VERSION ""

NS_ :

BS_:

BU_: EON XXX INTERCEPTOR ANY ACTUATOR SAFETY

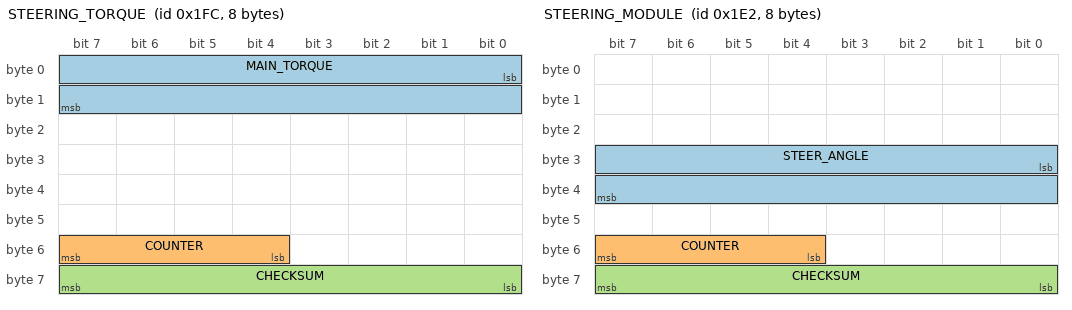
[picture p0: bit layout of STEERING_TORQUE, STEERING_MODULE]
BO_ 508 STEERING_TORQUE: 8 XXX
 SG_ MAIN_TORQUE : 0|16@1- (0.1,0) [0|65535] "" XXX
 SG_ COUNTER : 55|4@0+ (1,0) [0|15] "" XXX
 SG_ CHECKSUM : 56|8@1+ (1,0) [0|255] "" XXX

BO_ 482 STEERING_MODULE: 8 XXX
 SG_ STEER_ANGLE : 24|16@1- (0.1,0) [0|255] "" XXX
 SG_ COUNTER : 55|4@0+ (1,0) [0|15] "" XXX
 SG_ CHECKSUM : 56|8@1+ (1,0) [0|255] "" XXX

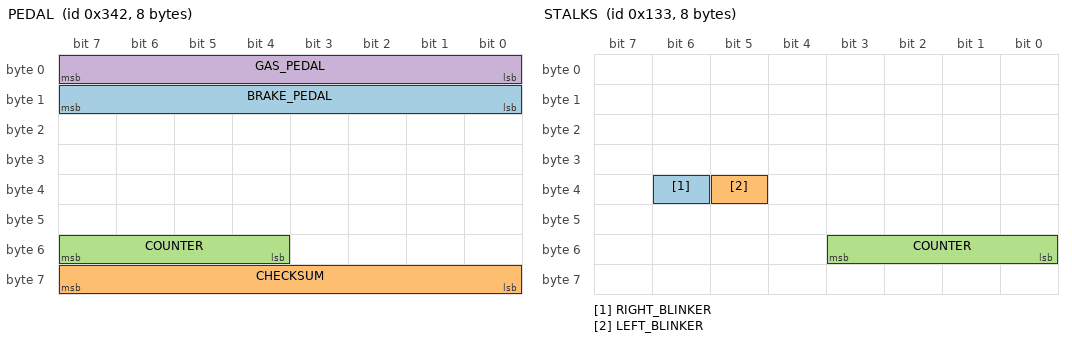
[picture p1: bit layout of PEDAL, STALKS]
BO_ 834 PEDAL: 8 XXX
 SG_ BRAKE_PEDAL : 8|8@1+ (0.01,0) [0|255] "" XXX
 SG_ CHECKSUM : 56|8@1+ (1,0) [0|255] "" XXX
 SG_ COUNTER : 55|4@0+ (1,0) [0|15] "" XXX
 SG_ GAS_PEDAL : 0|8@1+ (0.01,0) [0|255] "" XXX

BO_ 660 SEATBELT: 8 XXX
 SG_ SEATBELT_DRIVER : 17|1@0+ (1,0) [0|1] "" XXX

BO_ 307 STALKS: 8 XXX
 SG_ RIGHT_BLINKER : 38|1@0+ (1,0) [0|1] "" XXX
 SG_ LEFT_BLINKER : 37|1@0+ (1,0) [0|1] "" XXX
 SG_ COUNTER : 48|4@1+ (1,0) [0|15] "" XXX

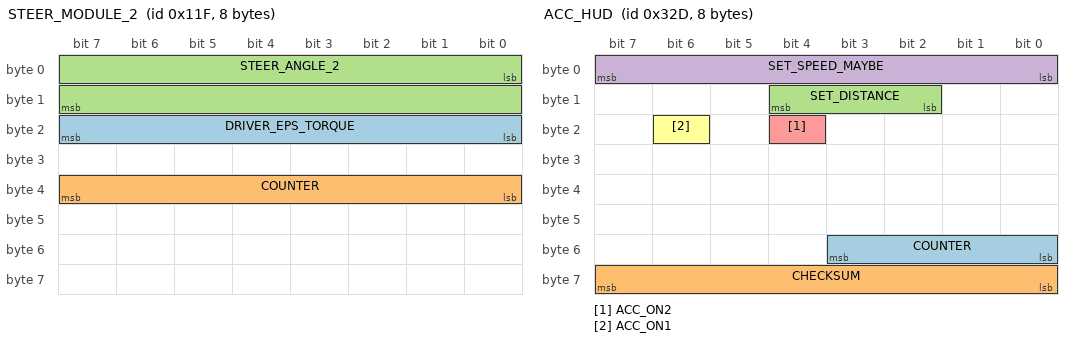
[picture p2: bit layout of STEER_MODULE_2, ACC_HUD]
BO_ 287 STEER_MODULE_2: 8 XXX
 SG_ DRIVER_EPS_TORQUE : 16|8@1+ (1,0) [0|255] "" XXX
 SG_ COUNTER : 39|8@0+ (1,0) [0|255] "" XXX
 SG_ STEER_ANGLE_2 : 0|16@1- (0.1,0) [0|65535] "" XXX

BO_ 944 PCM_BUTTONS: 8 XXX

BO_ 544 PEDAL_PRESSED: 8 XXX
 SG_ PEDAL_PRESSED_ACTIVE_LOW : 12|1@0+ (1,0) [0|1] "" XXX

BO_ 578 DRIVE_STATE: 8 XXX
 SG_ BRAKE_PRESSED : 37|1@0+ (1,0) [0|1] "" XXX
 SG_ GEAR : 40|3@1+ (1,0) [0|7] "" XXX

BO_ 813 ACC_HUD: 8 XXX
 SG_ COUNTER : 48|4@1+ (1,0) [0|15] "" XXX
 SG_ CHECKSUM : 56|8@1+ (1,0) [0|255] "" XXX
 SG_ SET_DISTANCE : 12|3@0+ (1,0) [0|7] "" XXX
 SG_ SET_SPEED_MAYBE : 0|8@1+ (1,0) [0|255] "" XXX
 SG_ ACC_ON2 : 20|1@0+ (1,0) [0|1] "" XXX
 SG_ ACC_ON1 : 22|1@0+ (1,0) [0|1] "" XXX

BO_ 790 LKAS_HUD: 8 XXX
 SG_ LKAS_ON : 36|1@0+ (1,0) [0|1] "" XXX

BO_ 814 ACC_RELATED: 8 XXX

BO_ 1048 BSM: 8 XXX
 SG_ LEFT_APPROACH : 23|1@0+ (1,0) [0|1] "" XXX
 SG_ BSM_RELATED : 24|1@0+ (1,0) [0|1] "" XXX

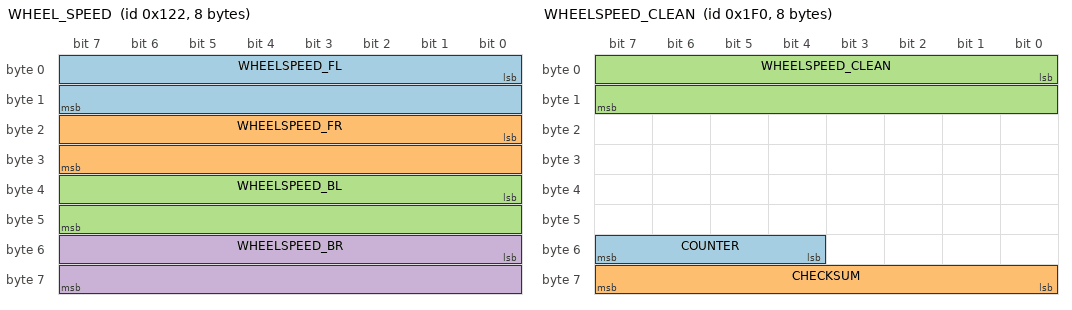
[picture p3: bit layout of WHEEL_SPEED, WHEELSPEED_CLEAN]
BO_ 290 WHEEL_SPEED: 8 XXX
 SG_ WHEELSPEED_FL : 0|16@1- (0.1,0) [0|65535] "" XXX
 SG_ WHEELSPEED_FR : 16|16@1+ (0.1,0) [0|65535] "" XXX
 SG_ WHEELSPEED_BL : 32|16@1+ (0.1,0) [0|65535] "" XXX
 SG_ WHEELSPEED_BR : 48|16@1+ (0.1,0) [0|65535] "" XXX

BO_ 496 WHEELSPEED_CLEAN: 8 XXX
 SG_ COUNTER : 55|4@0+ (1,0) [0|15] "" XXX
 SG_ CHECKSUM : 56|8@1+ (1,0) [0|255] "" XXX
 SG_ WHEELSPEED_CLEAN : 0|16@1+ (0.1,0) [0|65535] "" XXX

VAL_ 813 SET_DISTANCE 8 "4bar" 4 "3bar" 2 "2bar" 1 "1bar" ;
VAL_ 578 GEAR 4 "D" 2 "R" 1 "P" ;
